# SERDES_16G0 register map
Vendor: Texas Instruments
Registers are 32-bit, read-write, reset 0x0 unless marked. A register's access mark holds for its fields unless they carry their own. Offsets are as the file gives them; [hi:lo] are bit positions.

## SERDES_16G0 (part 2 of 5)
0x00 MACRO_ID_REG ro reset 0x7364
  [15:0] MACRO_ID_TYPE — ASCII representation of sd for SerDes type.
0x04 MACRO_ID_NUMBER_REG ro reset 0x3010000
  [31:16] MACRO_ID_NUMBER — Product family in binary coded decimal.
0x08 MACRO_ID_REV_REG ro reset 0x600 — Note this read-only field may vary from product to product.
  [15:0] MACRO_ID_REV — Revision number in binary coded decimal.
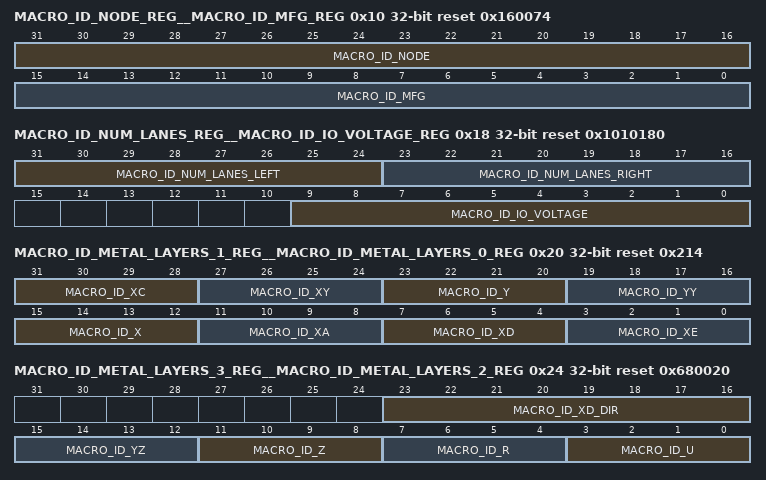
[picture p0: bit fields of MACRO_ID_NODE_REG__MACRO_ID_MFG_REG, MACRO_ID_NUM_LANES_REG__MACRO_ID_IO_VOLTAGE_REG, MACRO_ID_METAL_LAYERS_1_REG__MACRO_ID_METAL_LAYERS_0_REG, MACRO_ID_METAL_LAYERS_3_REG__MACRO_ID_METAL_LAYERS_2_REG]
0x10 MACRO_ID_NODE_REG__MACRO_ID_MFG_REG ro reset 0x160074 — Note this read-only field may vary from product to product.
  [31:16] MACRO_ID_NODE — Technology node in binary coded decimal
  [15:0] MACRO_ID_MFG — ASCII representation of the manufacturer.
0x14 MACRO_ID_FLAVOR_REG ro reset 0x6663 — Note this read-only field may vary from product to product.
  [15:0] MACRO_ID_FLAVOR — ASCII representation of fc for finfet compact flavor.
0x18 MACRO_ID_NUM_LANES_REG__MACRO_ID_IO_VOLTAGE_REG ro reset 0x1010180 — Note this read-only field may vary from product to product.
  [31:24] MACRO_ID_NUM_LANES_LEFT — The number of lanes on the left side of the common module in binary coded decimal.
  [23:16] MACRO_ID_NUM_LANES_RIGHT — The number of lanes on the right side of the common module in binary coded decimal.
  [9:0] MACRO_ID_IO_VOLTAGE — Product I/O voltage ID in binary coded decimal.
0x20 MACRO_ID_METAL_LAYERS_1_REG__MACRO_ID_METAL_LAYERS_0_REG ro reset 0x214 — Note this read-only field may vary from product to product.
  [31:28] MACRO_ID_XC — Number xc metals in stack up in binary decimal format.
  [27:24] MACRO_ID_XY — Number xy metals in stack up in binary decimal format.
  [23:20] MACRO_ID_Y — Number y metals in stack up in binary decimal format.
  [19:16] MACRO_ID_YY — Number yy metals in stack up in binary decimal format.
  [15:12] MACRO_ID_X — Number x metals in stack up in binary decimal format.
  [11:8] MACRO_ID_XA — Number xa metals in stack up in binary decimal format.
  [7:4] MACRO_ID_XD — Number xd metals in stack up in binary decimal format.
  [3:0] MACRO_ID_XE — Number xe metals in stack up in binary decimal format.
0x24 MACRO_ID_METAL_LAYERS_3_REG__MACRO_ID_METAL_LAYERS_2_REG ro reset 0x680020 — Note this read-only field may vary from product to product.
  [23:16] MACRO_ID_XD_DIR — Direction of xd metal in ASCII format.
  [15:12] MACRO_ID_YZ — Number yz metals in stack up in binary decimal format.
  [11:8] MACRO_ID_Z — Number z metals in stack up in binary decimal format.
  [7:4] MACRO_ID_R — Number r metals in stack up in binary decimal format.
  [3:0] MACRO_ID_U — Number u metals in stack up in binary decimal format.
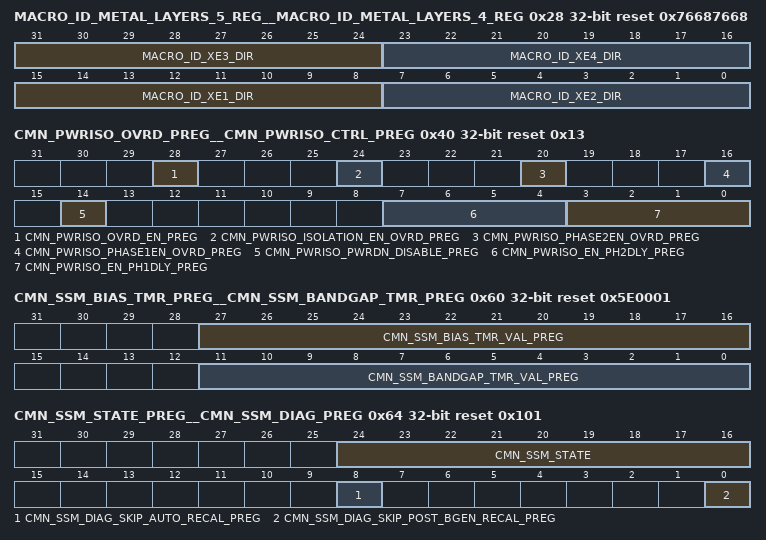
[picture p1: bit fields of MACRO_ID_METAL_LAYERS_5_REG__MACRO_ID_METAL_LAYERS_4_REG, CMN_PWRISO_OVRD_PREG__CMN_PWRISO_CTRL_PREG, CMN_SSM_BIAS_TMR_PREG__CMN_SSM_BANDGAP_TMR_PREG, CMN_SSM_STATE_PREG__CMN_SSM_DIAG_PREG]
0x28 MACRO_ID_METAL_LAYERS_5_REG__MACRO_ID_METAL_LAYERS_4_REG ro reset 0x76687668 — Note this read-only field may vary from product to product.
  [31:24] MACRO_ID_XE3_DIR — Direction of second highest lowest xe metal in ASCII format.
  [23:16] MACRO_ID_XE4_DIR — Direction of highest xe metal in ASCII format.
  [15:8] MACRO_ID_XE1_DIR — Direction of lowest xe metal in ASCII format.
  [7:0] MACRO_ID_XE2_DIR — Direction of second lowest xe metal in ASCII format.
0x40 CMN_PWRISO_OVRD_PREG__CMN_PWRISO_CTRL_PREG reset 0x13 — Common power-gated supply island control register.
  [28] CMN_PWRISO_OVRD_EN_PREG — cmn power gate active high override enable:
  [24] CMN_PWRISO_ISOLATION_EN_OVRD_PREG — cmn power gate isolation override:
  [20] CMN_PWRISO_PHASE2EN_OVRD_PREG — cmn power gate phase2en override:
  [16] CMN_PWRISO_PHASE1EN_OVRD_PREG — cmn_pwriso power gate phase1en override:
  [14] CMN_PWRISO_PWRDN_DISABLE_PREG — Power down disable:
  [7:4] CMN_PWRISO_EN_PH2DLY_PREG — Power enable phase 2 timer value:
  [3:0] CMN_PWRISO_EN_PH1DLY_PREG — Power enable phase 1 timer value:
0x60 CMN_SSM_BIAS_TMR_PREG__CMN_SSM_BANDGAP_TMR_PREG reset 0x5E0001 — Startup State Machine bandgap enable timer register.
  [27:16] CMN_SSM_BIAS_TMR_VAL_PREG — Bias enable state timer value :
  [11:0] CMN_SSM_BANDGAP_TMR_VAL_PREG — Bandgap enable state timer value :
0x64 CMN_SSM_STATE_PREG__CMN_SSM_DIAG_PREG access per field reset 0x101 — Startup State Machine diagnostic register.
  [24:16] CMN_SSM_STATE ro — Startup state machine current state:
  [8] CMN_SSM_DIAG_SKIP_AUTO_RECAL_PREG rw — Skip auto re-calibration enable : When this bit is active (1'b1), the auto calibration state will be skipped if it was previously run, unless the macro is disabled or reset.
  [0] CMN_SSM_DIAG_SKIP_POST_BGEN_RECAL_PREG rw — Skip post bandgap enable re-calibration : When this bit is active (1'b1), the post bandgap enable calibration state will be skipped if it was previously run, unless the macro is disabled or reset.
0x68 CMN_SMCSM_STATE_PREG ro — Startup State Machine Multi-cal State Machine current state register.
  [1:0] CMN_SMCSM_STATE — Startup State Machine Multi-cal State Machine current state register:
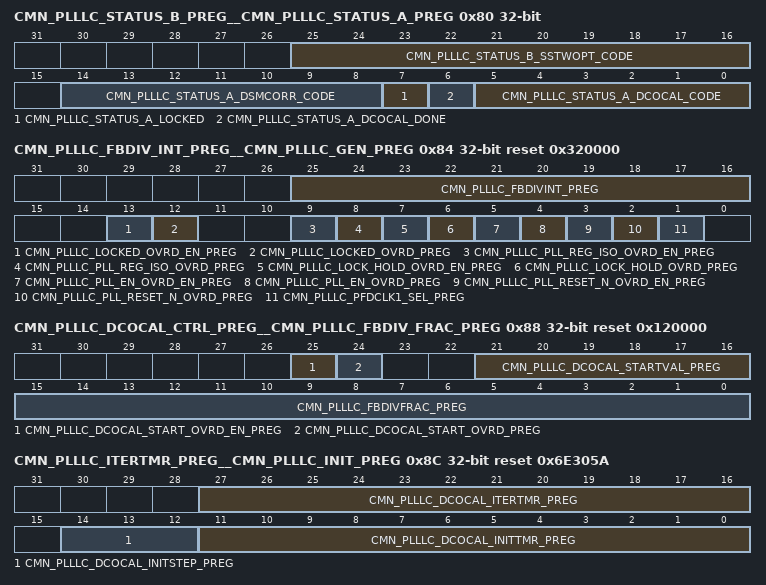
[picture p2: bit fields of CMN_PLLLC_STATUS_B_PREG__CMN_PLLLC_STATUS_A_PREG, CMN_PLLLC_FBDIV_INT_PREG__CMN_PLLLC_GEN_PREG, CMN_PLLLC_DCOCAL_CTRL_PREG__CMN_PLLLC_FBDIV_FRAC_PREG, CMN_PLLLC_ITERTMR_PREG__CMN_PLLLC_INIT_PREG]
0x80 CMN_PLLLC_STATUS_B_PREG__CMN_PLLLC_STATUS_A_PREG ro — PLLCMNLC status register A.
  [25:16] CMN_PLLLC_STATUS_B_SSTWOPT_CODE — Main PLLLC Spread Spectrum two point value result:
  [14:8] CMN_PLLLC_STATUS_A_DSMCORR_CODE — PLLCMNLC DSM spur correction code result:
  [7] CMN_PLLLC_STATUS_A_LOCKED — PLLCMNLC locked Status:
  [6] CMN_PLLLC_STATUS_A_DCOCAL_DONE — PLLCMNLC DCO calibration status:
  [5:0] CMN_PLLLC_STATUS_A_DCOCAL_CODE — PLLCMNLC DCO calibration code result:
0x84 CMN_PLLLC_FBDIV_INT_PREG__CMN_PLLLC_GEN_PREG reset 0x320000 — PLLCMNLC general control register.
  [25:16] CMN_PLLLC_FBDIVINT_PREG — This value sets the mode dependent PLLCMNLC fbdivint value.
  [13] CMN_PLLLC_LOCKED_OVRD_EN_PREG — PLLCMNLC locked active high override enable:
  [12] CMN_PLLLC_LOCKED_OVRD_PREG — PLLCMNLC locked signal force:
  [9] CMN_PLLLC_PLL_REG_ISO_OVRD_EN_PREG — PLLCMNLC regulator isolation active high override enable
  [8] CMN_PLLLC_PLL_REG_ISO_OVRD_PREG — When cmn_plllc_pll_reg_iso_ovrd_en_preg is asserted high, overrides the state dependent PLLCMNLC regulator isolation value.
  [7] CMN_PLLLC_LOCK_HOLD_OVRD_EN_PREG — Lock detection hold function active high override enable.
  [6] CMN_PLLLC_LOCK_HOLD_OVRD_PREG — When cmn_plllc_lock_hold_ovrd_en_preg is asserted high, overrides the state dependent lock detect function value.
  [5] CMN_PLLLC_PLL_EN_OVRD_EN_PREG — PLLCMNLC enable active high override enable
  [4] CMN_PLLLC_PLL_EN_OVRD_PREG — When cmn_plllc_pll_en_ovrd_en_preg is asserted high, overrides the state dependent PLLCMNLC enable value.
  [3] CMN_PLLLC_PLL_RESET_N_OVRD_EN_PREG — PLLCMNLC active high reset override enable.
  [2] CMN_PLLLC_PLL_RESET_N_OVRD_PREG — When cmn_plllc_pll_reset_n_ovrd_en_preg is asserted high, overrides the state dependent PLLCMNLC active low reset value.
  [1] CMN_PLLLC_PFDCLK1_SEL_PREG — When asserted the pfdclk1 is used as the reference clock, When deasserted, pfdclk is used.
0x88 CMN_PLLLC_DCOCAL_CTRL_PREG__CMN_PLLLC_FBDIV_FRAC_PREG reset 0x120000 — PLLCMNLC fractional feedback divider register.
  [25] CMN_PLLLC_DCOCAL_START_OVRD_EN_PREG — DCO calibration start active high override enable.
  [24] CMN_PLLLC_DCOCAL_START_OVRD_PREG — When cmn_plllc_dcocal_start_ovrd_en_preg is asserted high, this value overrides the mode dependent DCO calibration start value.
  [21:16] CMN_PLLLC_DCOCAL_STARTVAL_PREG — This value sets the DCO calibration startval value.
  [15:0] CMN_PLLLC_FBDIVFRAC_PREG — This value sets the mode dependent PLLCMNLC fbdivfrac value.
0x8C CMN_PLLLC_ITERTMR_PREG__CMN_PLLLC_INIT_PREG reset 0x6E305A — PLLCMNLC DCO calibration initialization register.
  [27:16] CMN_PLLLC_DCOCAL_ITERTMR_PREG — This value sets the DCO calibration iteration timer value.
  [14:12] CMN_PLLLC_DCOCAL_INITSTEP_PREG — This value sets the DCO calibration initialization step value.
  [11:0] CMN_PLLLC_DCOCAL_INITTMR_PREG — This value sets the DCO calibration initialization timer value.
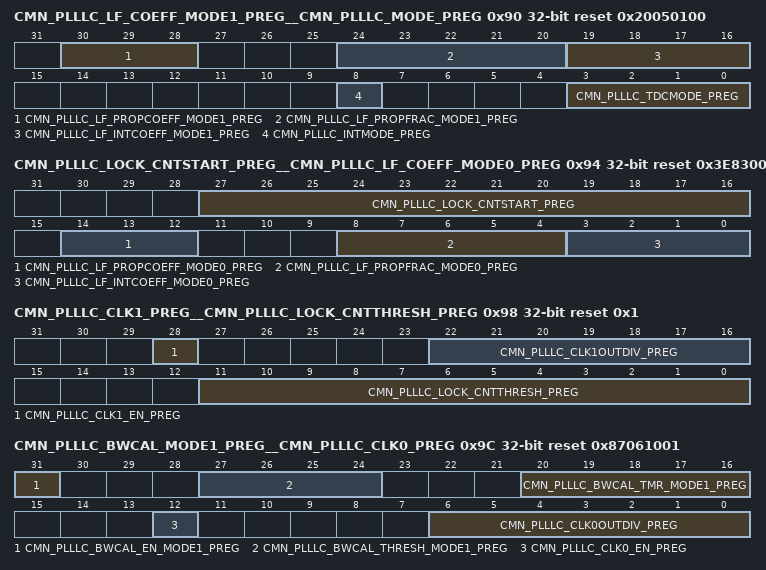
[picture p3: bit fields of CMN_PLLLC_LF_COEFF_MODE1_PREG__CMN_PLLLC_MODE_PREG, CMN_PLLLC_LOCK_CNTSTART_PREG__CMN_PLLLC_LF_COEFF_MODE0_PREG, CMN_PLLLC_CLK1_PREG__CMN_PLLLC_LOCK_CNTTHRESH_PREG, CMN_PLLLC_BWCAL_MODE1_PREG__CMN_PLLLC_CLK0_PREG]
0x90 CMN_PLLLC_LF_COEFF_MODE1_PREG__CMN_PLLLC_MODE_PREG reset 0x20050100 — PLLCMNLC mode register.
  [30:28] CMN_PLLLC_LF_PROPCOEFF_MODE1_PREG — This value sets the loop filter proportional coefficient value when cmn_plllc_mode is asserted.
  [24:20] CMN_PLLLC_LF_PROPFRAC_MODE1_PREG — This value sets the loop filter fractional coefficient value when cmn_plllc_mode is asserted.
  [19:16] CMN_PLLLC_LF_INTCOEFF_MODE1_PREG — This value sets the loop filter integer coefficient value when cmn_plllc_mode is asserted.
  [8] CMN_PLLLC_INTMODE_PREG — This value sets the integer mode value.
  [3:0] CMN_PLLLC_TDCMODE_PREG — This value sets the TDC mode value.
0x94 CMN_PLLLC_LOCK_CNTSTART_PREG__CMN_PLLLC_LF_COEFF_MODE0_PREG reset 0x3E83006 — PLLCMNLC loop filter register for mode 0.
  [27:16] CMN_PLLLC_LOCK_CNTSTART_PREG — This value sets the lock counter start value.
  [14:12] CMN_PLLLC_LF_PROPCOEFF_MODE0_PREG — This value sets the loop filter proportional coefficient value when cmn_plllc_mode is deasserted.
  [8:4] CMN_PLLLC_LF_PROPFRAC_MODE0_PREG — This value sets the loop filter fractional coefficient value when cmn_plllc_mode is deasserted.
  [3:0] CMN_PLLLC_LF_INTCOEFF_MODE0_PREG — This value sets the loop filter integer coefficient value when cmn_plllc_mode is deasserted.
0x98 CMN_PLLLC_CLK1_PREG__CMN_PLLLC_LOCK_CNTTHRESH_PREG reset 0x1 — PLLCMNLC lock count threshold register.
  [28] CMN_PLLLC_CLK1_EN_PREG — This value sets the clock1 enable value.
  [22:16] CMN_PLLLC_CLK1OUTDIV_PREG — This value sets the clock1 output divider value.
  [11:0] CMN_PLLLC_LOCK_CNTTHRESH_PREG — PLLCMNLC lock counter threshold value :
0x9C CMN_PLLLC_BWCAL_MODE1_PREG__CMN_PLLLC_CLK0_PREG reset 0x87061001 — PLLCMNLC clock0 register.
  [31] CMN_PLLLC_BWCAL_EN_MODE1_PREG — This value sets the bwcal enable value when cmn_plllc_mode is asserted.
  [27:24] CMN_PLLLC_BWCAL_THRESH_MODE1_PREG — This value sets the bwcal threshold value when cmn_plllc_mode is asserted.
  [20:16] CMN_PLLLC_BWCAL_TMR_MODE1_PREG — This value sets the bwcal timer value when cmn_plllc_mode is asserted.
  [12] CMN_PLLLC_CLK0_EN_PREG — This value sets the clock0 enable value.
  [6:0] CMN_PLLLC_CLK0OUTDIV_PREG — This value sets the clock0 output divider value.
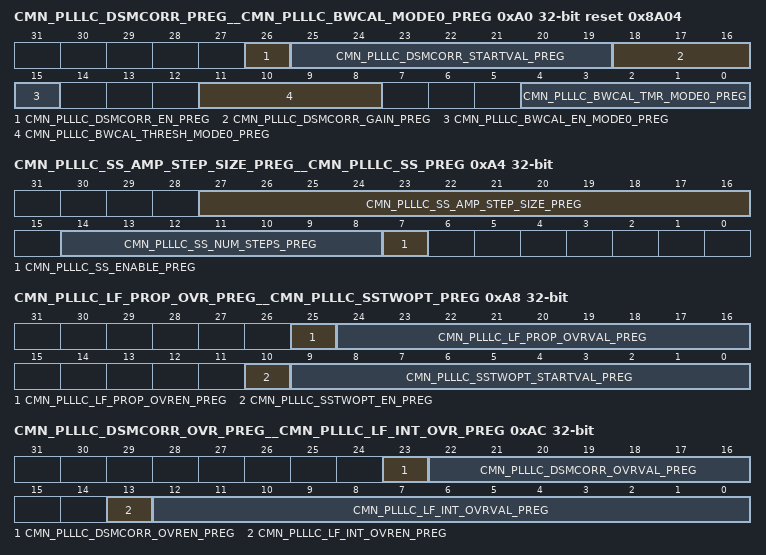
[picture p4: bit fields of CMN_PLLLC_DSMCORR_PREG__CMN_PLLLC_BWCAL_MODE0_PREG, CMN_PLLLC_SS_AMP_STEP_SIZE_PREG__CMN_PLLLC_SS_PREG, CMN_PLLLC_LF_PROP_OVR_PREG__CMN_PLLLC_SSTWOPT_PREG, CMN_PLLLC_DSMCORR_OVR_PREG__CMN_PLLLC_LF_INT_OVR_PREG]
0xA0 CMN_PLLLC_DSMCORR_PREG__CMN_PLLLC_BWCAL_MODE0_PREG reset 0x8A04 — PLLCMNLC bandwidth cal register for mode 0.
  [26] CMN_PLLLC_DSMCORR_EN_PREG — This value sets the DSM spur correction coefficient enable value.
  [25:19] CMN_PLLLC_DSMCORR_STARTVAL_PREG — This value sets the DSM spur correction coefficient startval value.
  [18:16] CMN_PLLLC_DSMCORR_GAIN_PREG — This value sets the DSM spur correction coefficient gain value.
  [15] CMN_PLLLC_BWCAL_EN_MODE0_PREG — This value sets the bwcal enable value when cmn_plllc_mode is deasserted.
  [11:8] CMN_PLLLC_BWCAL_THRESH_MODE0_PREG — This value sets the bwcal threhsold value when cmn_plllc_mode is deasserted.
  [4:0] CMN_PLLLC_BWCAL_TMR_MODE0_PREG — This value sets the bwcal timer value when cmn_plllc_mode is deasserted.
0xA4 CMN_PLLLC_SS_AMP_STEP_SIZE_PREG__CMN_PLLLC_SS_PREG — PLLCMNLC spread spectrum register.
  [27:16] CMN_PLLLC_SS_AMP_STEP_SIZE_PREG — This value sets the spread spectrum amp step size value.
  [14:8] CMN_PLLLC_SS_NUM_STEPS_PREG — This value sets the spread spectrum number of steps value.
  [7] CMN_PLLLC_SS_ENABLE_PREG — This value sets the spread spectrum enable value.
0xA8 CMN_PLLLC_LF_PROP_OVR_PREG__CMN_PLLLC_SSTWOPT_PREG — PLLCMNLC spread spectrum two point register.
  [25] CMN_PLLLC_LF_PROP_OVREN_PREG — Drives the lfprop_ovren pin on the PLLCMNLC.
  [24:16] CMN_PLLLC_LF_PROP_OVRVAL_PREG — Drives the lfprop_ovrval on the PLLCMNLC.
  [10] CMN_PLLLC_SSTWOPT_EN_PREG — This value sets the sstwopt_en pin on the PLL.
  [9:0] CMN_PLLLC_SSTWOPT_STARTVAL_PREG — This value sets the sstwoopt_startval pins on the PLL.
0xAC CMN_PLLLC_DSMCORR_OVR_PREG__CMN_PLLLC_LF_INT_OVR_PREG — PLLCMNLC debug and test loop filter integer override register.
  [23] CMN_PLLLC_DSMCORR_OVREN_PREG — Drives the dsmcorr_ovren port on the PLLCMNLC.
  [22:16] CMN_PLLLC_DSMCORR_OVRVAL_PREG — Drives the dsmcorr_ovrval port on the PLLCMNLC.
  [13] CMN_PLLLC_LF_INT_OVREN_PREG — Drives the lf_int_ovren pin on the PLLCMNLC.
  [12:0] CMN_PLLLC_LF_INT_OVRVAL_PREG — Drives the lf_int_ovrval pin on the PLLCMNLC.
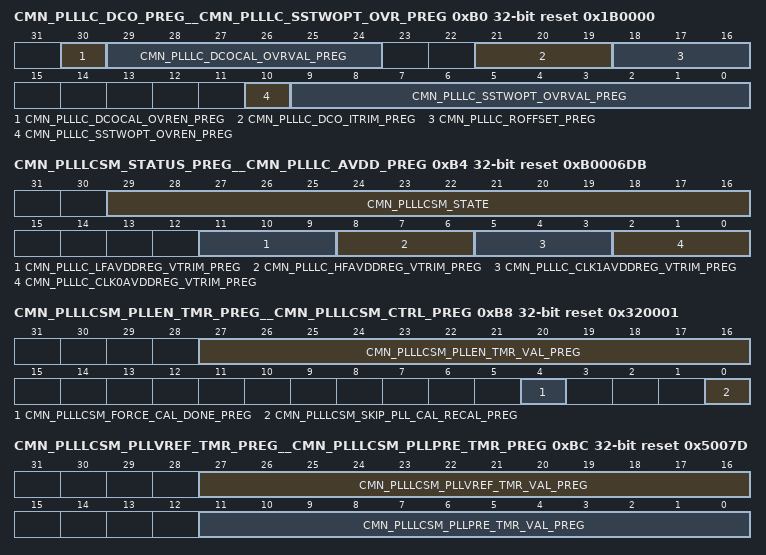
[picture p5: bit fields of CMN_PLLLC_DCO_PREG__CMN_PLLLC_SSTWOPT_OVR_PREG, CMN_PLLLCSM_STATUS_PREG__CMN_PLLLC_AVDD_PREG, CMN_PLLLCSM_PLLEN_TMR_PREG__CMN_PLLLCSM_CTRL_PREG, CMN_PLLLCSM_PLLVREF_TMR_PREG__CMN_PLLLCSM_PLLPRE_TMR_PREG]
0xB0 CMN_PLLLC_DCO_PREG__CMN_PLLLC_SSTWOPT_OVR_PREG reset 0x1B0000 — PLLCMNLC debug and test loop Spread Spectrum two point override register.
  [30] CMN_PLLLC_DCOCAL_OVREN_PREG — When asserted the cmnda_plllc_dcocal_ovren which drives the dcocal_ovren port on the PLLCMNLC is forced high.
  [29:24] CMN_PLLLC_DCOCAL_OVRVAL_PREG — When cmnda_plllc_dcocal_ovren is asserted, this value is driven onto cmnda_plllc_dcocal_ovrval which drives the dcocal_ovrval port on the PLLCMNLC.
  [21:19] CMN_PLLLC_DCO_ITRIM_PREG — Drives the DCO trim current on the PLLCMNLC.
  [18:16] CMN_PLLLC_ROFFSET_PREG — DCO tank offset resistor trim.
  [10] CMN_PLLLC_SSTWOPT_OVREN_PREG — Drives the sstwopt_ovren port on the PLLCMNLC.
  [9:0] CMN_PLLLC_SSTWOPT_OVRVAL_PREG — Drives the sstwopt_ovrval port on the PLLCMNLC.
0xB4 CMN_PLLLCSM_STATUS_PREG__CMN_PLLLC_AVDD_PREG access per field reset 0xB0006DB — PLLCMNLC debug and test avdd register.
  [29:16] CMN_PLLLCSM_STATE ro — State machine state register.
  [11:9] CMN_PLLLC_LFAVDDREG_VTRIM_PREG rw — Drives the lfavddreg_vtrim port on the PLLCMNLC.
  [8:6] CMN_PLLLC_HFAVDDREG_VTRIM_PREG rw — Drives the hfavddreg_vtrim port on the PLLCMNLC.
  [5:3] CMN_PLLLC_CLK1AVDDREG_VTRIM_PREG rw — Drives the clk1avddreg_vtrim port on the PLLCMNLC.
  [2:0] CMN_PLLLC_CLK0AVDDREG_VTRIM_PREG rw — Drives the clk0avddreg_vtrim port on the PLLCMNLC.
0xB8 CMN_PLLLCSM_PLLEN_TMR_PREG__CMN_PLLLCSM_CTRL_PREG reset 0x320001 — PLLCMNLC Control State Machine Control register.
  [27:16] CMN_PLLLCSM_PLLEN_TMR_VAL_PREG — PLL enable state timer value :
  [4] CMN_PLLLCSM_FORCE_CAL_DONE_PREG — Asserting this bit immediately advances the State Machine from the PLLSM_CAL state currently in or once entered.
  [0] CMN_PLLLCSM_SKIP_PLL_CAL_RECAL_PREG — Skip PLL calibration re-calibration enable :
0xBC CMN_PLLLCSM_PLLVREF_TMR_PREG__CMN_PLLLCSM_PLLPRE_TMR_PREG reset 0x5007D — PLLCMNLC Control State Machine PLL pre-charge timer register.
  [27:16] CMN_PLLLCSM_PLLVREF_TMR_VAL_PREG — PLL pre-charge state timer value :
  [11:0] CMN_PLLLCSM_PLLPRE_TMR_VAL_PREG — PLL pre-charge state timer value :
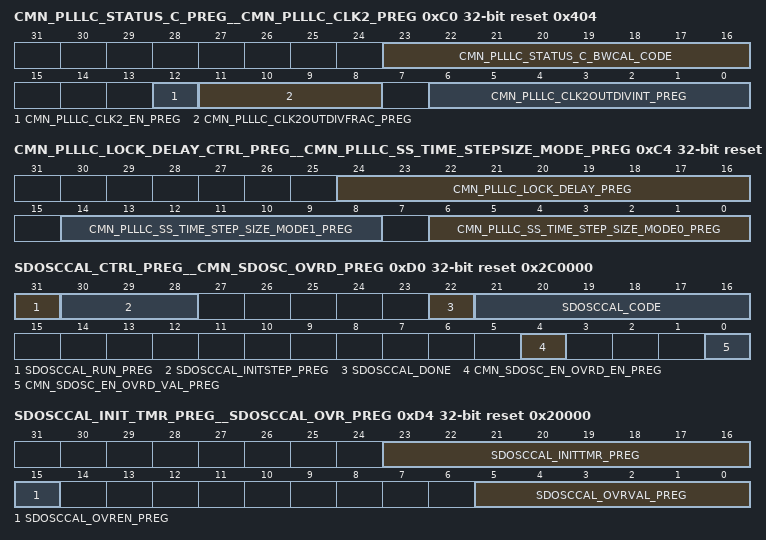
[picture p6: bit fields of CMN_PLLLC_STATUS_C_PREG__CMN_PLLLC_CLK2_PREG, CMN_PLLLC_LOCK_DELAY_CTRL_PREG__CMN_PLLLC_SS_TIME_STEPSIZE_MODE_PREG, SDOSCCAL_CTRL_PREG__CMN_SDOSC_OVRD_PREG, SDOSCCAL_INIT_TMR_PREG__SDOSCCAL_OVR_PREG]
0xC0 CMN_PLLLC_STATUS_C_PREG__CMN_PLLLC_CLK2_PREG access per field reset 0x404 — PLLCMNLC clock2 register.
  [23:16] CMN_PLLLC_STATUS_C_BWCAL_CODE ro — PLLCMNLC Band Width calibration code result:
  [12] CMN_PLLLC_CLK2_EN_PREG rw — This value sets the clock2 enable value.
  [11:8] CMN_PLLLC_CLK2OUTDIVFRAC_PREG rw — This value sets the clock2 fractional output divider's fraction value:
  [6:0] CMN_PLLLC_CLK2OUTDIVINT_PREG rw — This value sets the clock2 fractional output divider's integer value.
0xC4 CMN_PLLLC_LOCK_DELAY_CTRL_PREG__CMN_PLLLC_SS_TIME_STEPSIZE_MODE_PREG reset 0x808 — PLLCMNLC spread spectrum Time Step Size Mode register.
  [24:16] CMN_PLLLC_LOCK_DELAY_PREG — This value sets a delay from internal lock assertion to assertion of cmn_plllc_locked.
  [14:8] CMN_PLLLC_SS_TIME_STEP_SIZE_MODE1_PREG — This value sets the spread spectrum time step size value when cmn_plllc_mode is asserted.
  [6:0] CMN_PLLLC_SS_TIME_STEP_SIZE_MODE0_PREG — This value sets the spread spectrum time step size value when cmn_plllc_mode is deasserted.
0xD0 SDOSCCAL_CTRL_PREG__CMN_SDOSC_OVRD_PREG access per field reset 0x2C0000 — Signal detection oscillator override register
  [31] SDOSCCAL_RUN_PREG rw — Signal detection oscillator calibration manual initiation active high enable.
  [30:28] SDOSCCAL_INITSTEP_PREG rw — Signal detection oscillator calibration initial step size.
  [22] SDOSCCAL_DONE ro — Signal detection oscillator calibration active high complete flag.
  [21:16] SDOSCCAL_CODE ro — Signal detection oscillator calibration result.
  [4] CMN_SDOSC_EN_OVRD_EN_PREG rw — Active high override enable for the signal detection oscillator circuit enable.
  [0] CMN_SDOSC_EN_OVRD_VAL_PREG rw — When cmn_sdosc_en_ovrd_en_preg is asserted, this value drives the cmnda_sdosc_en circuit enable.
0xD4 SDOSCCAL_INIT_TMR_PREG__SDOSCCAL_OVR_PREG reset 0x20000 — Signal detection oscillator calibration override register
  [23:16] SDOSCCAL_INITTMR_PREG — Signal detection calibration initial wait timer to allow the analog circuits to settle on initiation of the calibration sequence.
  [15] SDOSCCAL_OVREN_PREG — Signal detection oscillator override active high enable.
  [5:0] SDOSCCAL_OVRVAL_PREG — When sdosccal_ovren_pregis asserted high, this value is used by the Signal detection oscillator rather than the calibration engine result.
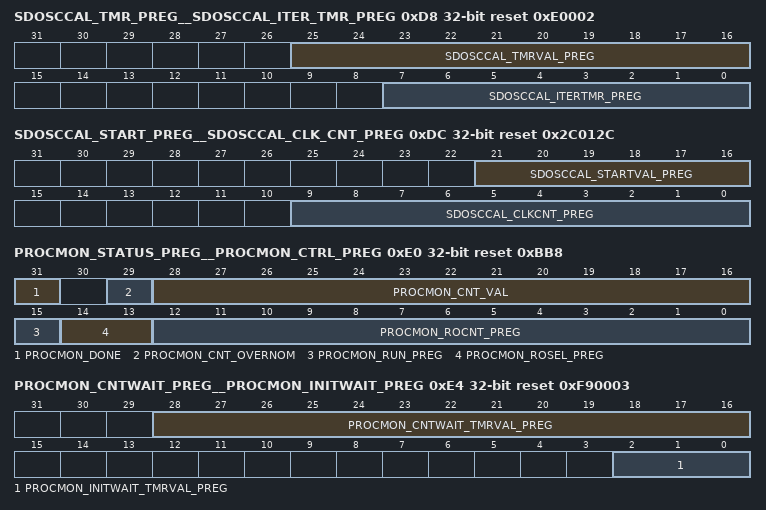
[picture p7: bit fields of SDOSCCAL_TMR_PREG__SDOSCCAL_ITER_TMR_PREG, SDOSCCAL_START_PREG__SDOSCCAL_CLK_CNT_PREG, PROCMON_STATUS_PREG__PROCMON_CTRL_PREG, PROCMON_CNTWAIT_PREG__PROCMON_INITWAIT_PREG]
0xD8 SDOSCCAL_TMR_PREG__SDOSCCAL_ITER_TMR_PREG reset 0xE0002 — Signal detection oscillator calibration iteration timer register
  [25:16] SDOSCCAL_TMRVAL_PREG — This value sets the Signal detection oscillator frequency evaluation time.
  [7:0] SDOSCCAL_ITERTMR_PREG — Signal detection calibration wait timer to allow the analog circuits to settle to the new frequency after a calibration code change.
0xDC SDOSCCAL_START_PREG__SDOSCCAL_CLK_CNT_PREG reset 0x2C012C — Signal detection oscillator calibration oscillator clock count target register
  [21:16] SDOSCCAL_STARTVAL_PREG — This value sets the Signal detection oscillator calibration starting code.
  [9:0] SDOSCCAL_CLKCNT_PREG — This value sets the Signal detection oscillator expected clock count target.
0xE0 PROCMON_STATUS_PREG__PROCMON_CTRL_PREG access per field reset 0xBB8 — Process Monitor control register.
  [31] PROCMON_DONE ro — Active high process monitor ring oscillator count complete flag.
  [29] PROCMON_CNT_OVERNOM ro — When asserted this bit indicates the process monitor ring oscillator counter reached the value expected for a nominal PVT part, as established by procmon_rocnt_preg.
  [28:16] PROCMON_CNT_VAL ro — Process monitor ring oscillator counter value.
  [15] PROCMON_RUN_PREG rw — Active high process monitor counter start.
  [14:13] PROCMON_ROSEL_PREG rw — Process monitor ring oscillator select:
  [12:0] PROCMON_ROCNT_PREG rw — Expected oscillator clocks counted for nominal process at typical conditions:
0xE4 PROCMON_CNTWAIT_PREG__PROCMON_INITWAIT_PREG reset 0xF90003 — Process Monitor initial wait timer register.
  [28:16] PROCMON_CNTWAIT_TMRVAL_PREG — Time to count the selected ring oscillator clocks.
  [2:0] PROCMON_INITWAIT_TMRVAL_PREG — Nominal number of cmn_refclk_gated clock periods to wait while the analog circuit powers up and the enabled ring oscillator settles.
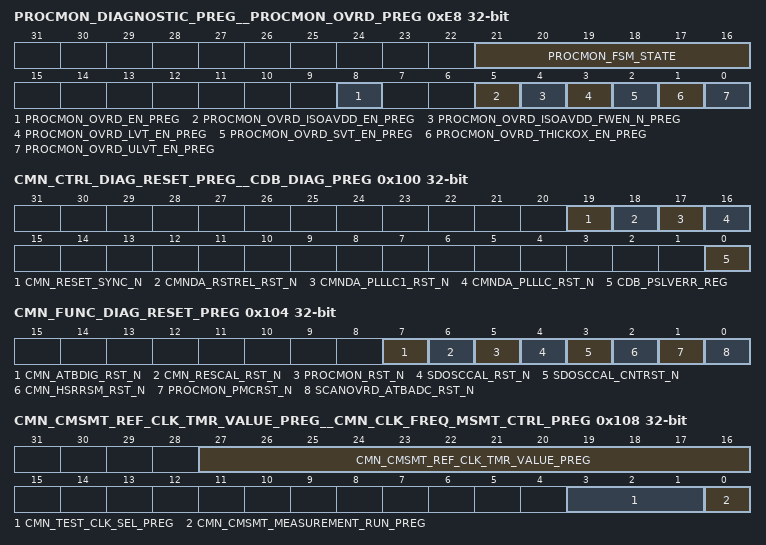
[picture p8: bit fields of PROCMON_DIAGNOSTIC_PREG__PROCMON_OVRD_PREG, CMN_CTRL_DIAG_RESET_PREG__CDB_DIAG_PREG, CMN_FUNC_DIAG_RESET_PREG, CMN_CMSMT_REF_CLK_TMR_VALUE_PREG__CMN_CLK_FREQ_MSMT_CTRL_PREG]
0xE8 PROCMON_DIAGNOSTIC_PREG__PROCMON_OVRD_PREG access per field — Process monitor override register.
  [21:16] PROCMON_FSM_STATE ro — Process monitor state machine state vector.
  [8] PROCMON_OVRD_EN_PREG rw — Active high analog control override enable.
  [5] PROCMON_OVRD_ISOAVDD_EN_PREG rw — When procmon_ovrd_en_preg is asserted, this value overrides the analog circuit's power gate enable, cmnda_pmc_isoavdd_en.
  [4] PROCMON_OVRD_ISOAVDD_FWEN_N_PREG rw — When procmon_ovrd_en_preg is asserted, this value overrides the power gate isolation control, cmnda_pmc_isoavdd_fwen_n.
  [3] PROCMON_OVRD_LVT_EN_PREG rw — When procmon_ovrd_en_preg is asserted, this value overrides the analog circuit's LVT ring oscillator enable, cmnda_pmc_lvt_en.
  [2] PROCMON_OVRD_SVT_EN_PREG rw — When procmon_ovrd_en_preg is asserted, this value overrides the analog circuit's SVT ring oscillator enable, cmnda_pmc_svt_en.
  [1] PROCMON_OVRD_THICKOX_EN_PREG rw — When procmon_ovrd_en_preg is asserted, this value overrides the analog circuit's thick oxide ring oscillator enable, cmnda_pmc_thickox_en.
  [0] PROCMON_OVRD_ULVT_EN_PREG rw — When procmon_ovrd_en_preg is asserted, this value overrides the analog circuit's ULVT ring oscillator enable, cmnda_pmc_ulvt_en.
0x100 CMN_CTRL_DIAG_RESET_PREG__CDB_DIAG_PREG ro — CDB diagnostic register.
  [19] CMN_RESET_SYNC_N — Current state of the cmn_reset_sync_n reset.
  [18] CMNDA_RSTREL_RST_N — Current state of the cmnda_rstrel_rst_n reset.
  [17] CMNDA_PLLLC1_RST_N — Current state of the cmnda_plllc1_rst_n reset.
  [16] CMNDA_PLLLC_RST_N — Current state of the cmnda_plllc_rst_n reset.
  [0] CDB_PSLVERR_REG — CDB bus error :
0x104 CMN_FUNC_DIAG_RESET_PREG ro — Common functions submodule reset diagnostic register.
  [7] CMN_ATBDIG_RST_N — Current state of the cmn_atbdig_rst_n reset.
  [6] CMN_RESCAL_RST_N — Current state of the cmn_rescal_rst_n reset.
  [5] PROCMON_RST_N — Current state of the procmon_rst_n reset.
  [4] SDOSCCAL_RST_N — Current state of the sdosccal_rst_n reset.
  [3] SDOSCCAL_CNTRST_N — Current state of the sdosccal_cntrst_n reset.
  [2] CMN_HSRRSM_RST_N — Current state of the cmn_hsrrsm_rst_n reset.
  [1] PROCMON_PMCRST_N — Current state of the procmon_pmcrst_n reset.
  [0] SCANOVRD_ATBADC_RST_N — Current state of the scanovrd_atbadc_rst_n reset.
0x108 CMN_CMSMT_REF_CLK_TMR_VALUE_PREG__CMN_CLK_FREQ_MSMT_CTRL_PREG — Common clock frequency measurement control register.
  [27:16] CMN_CMSMT_REF_CLK_TMR_VALUE_PREG — Reference clock timer value :
  [3:1] CMN_TEST_CLK_SEL_PREG — Test clock selection:
  [0] CMN_CMSMT_MEASUREMENT_RUN_PREG — Test clock measurement active high enable:
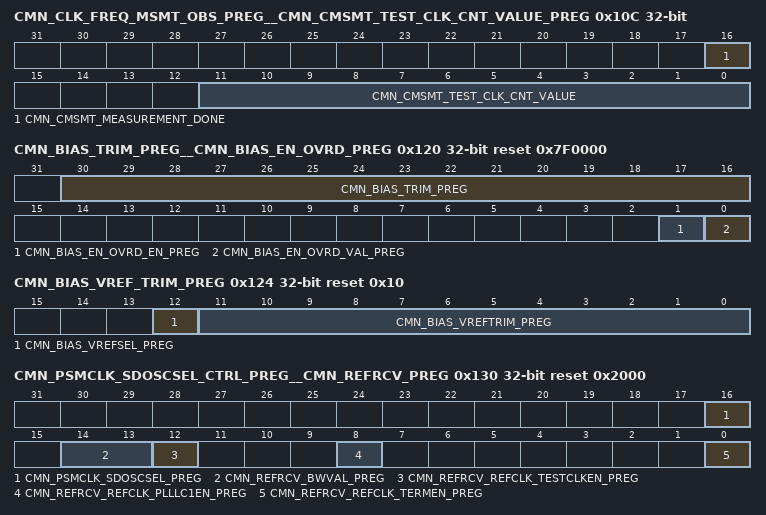
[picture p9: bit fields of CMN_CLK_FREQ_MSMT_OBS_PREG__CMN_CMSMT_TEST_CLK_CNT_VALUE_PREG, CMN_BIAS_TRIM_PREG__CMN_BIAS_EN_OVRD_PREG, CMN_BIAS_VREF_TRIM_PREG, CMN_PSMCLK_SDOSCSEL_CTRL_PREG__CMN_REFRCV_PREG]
0x10C CMN_CLK_FREQ_MSMT_OBS_PREG__CMN_CMSMT_TEST_CLK_CNT_VALUE_PREG ro — Common clock frequency measurement result register.
  [16] CMN_CMSMT_MEASUREMENT_DONE — Test clock measurement done:
  [11:0] CMN_CMSMT_TEST_CLK_CNT_VALUE — Test clock counter value:
0x110 CMN_SPARE_REG_PREG — Common spare registers to analog.
  [15:0] SPARE_PREG — Spare register bits assigned to cmnda_sparecdb.
0x120 CMN_BIAS_TRIM_PREG__CMN_BIAS_EN_OVRD_PREG reset 0x7F0000 — Bias diagnostic override register.
  [30:16] CMN_BIAS_TRIM_PREG — Drives the cmn_ana_bias block's thermometer encoded bus:
  [1] CMN_BIAS_EN_OVRD_EN_PREG — cmn_ana_bias enable active high override enable.
  [0] CMN_BIAS_EN_OVRD_VAL_PREG — When cmn_bias_en_ovrd_en_preg is asserted high, this value overrides the normal mission-mode bias enable.
0x124 CMN_BIAS_VREF_TRIM_PREG reset 0x10 — Bias debug and test voltage reference trim register.
  [12] CMN_BIAS_VREFSEL_PREG — Drives the cmn_ana_bias block vrefsel to select for voltage reference source:
  [11:0] CMN_BIAS_VREFTRIM_PREG — Drives the cmn_ana_bias block's vreftrim setting the resistor ladder voltage reference trim.
0x130 CMN_PSMCLK_SDOSCSEL_CTRL_PREG__CMN_REFRCV_PREG reset 0x2000 — Reference clock receiver register.
  [16] CMN_PSMCLK_SDOSCSEL_PREG — cmn_psmclk_out source select.
  [14:13] CMN_REFRCV_BWVAL_PREG — Bus to control the receiver bandwidth.
  [12] CMN_REFRCV_REFCLK_TESTCLKEN_PREG — Active high enable for CMOS only path from cmn_refclk_p to the digital.
  [8] CMN_REFRCV_REFCLK_PLLLC1EN_PREG — Active high enable for refclk driver to PLLCMNLC1.
  [0] CMN_REFRCV_REFCLK_TERMEN_PREG — Active high termination enable for the refclk receiver.
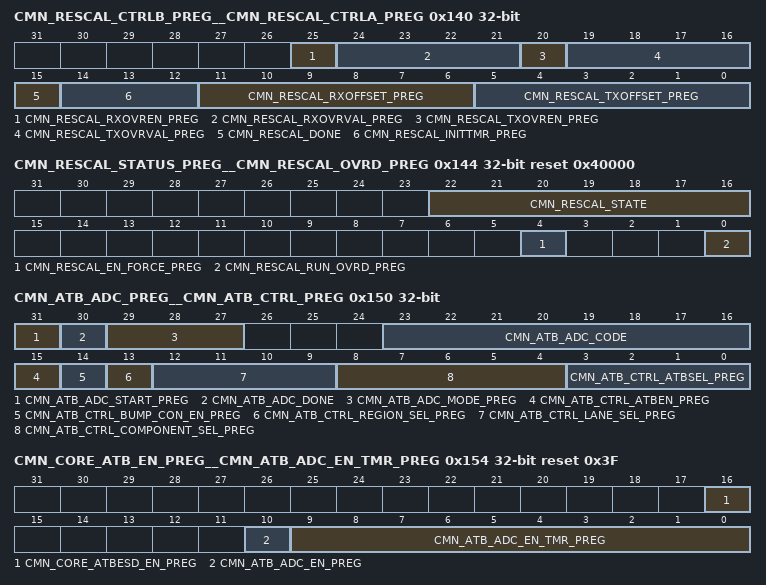
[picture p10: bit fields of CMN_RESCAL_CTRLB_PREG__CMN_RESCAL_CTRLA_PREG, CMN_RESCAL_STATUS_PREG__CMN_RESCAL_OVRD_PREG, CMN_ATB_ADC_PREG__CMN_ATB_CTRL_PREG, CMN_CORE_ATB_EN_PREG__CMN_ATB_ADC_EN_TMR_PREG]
0x140 CMN_RESCAL_CTRLB_PREG__CMN_RESCAL_CTRLA_PREG access per field — Resistor calibration debug and test control register A.
  [25] CMN_RESCAL_RXOVREN_PREG rw — RX resistor calibration LUT value active high override enable.
  [24:21] CMN_RESCAL_RXOVRVAL_PREG rw — When cmn_rescal_rxovren_preg is asserted, this value overrides the RX resistor calibration LUT value.
  [20] CMN_RESCAL_TXOVREN_PREG rw — TX resistor calibration LUT value active high override enable.
  [19:16] CMN_RESCAL_TXOVRVAL_PREG rw — When cmn_rescal_txovren_preg is asserted, this value overrides the TX resistor calibration LUT value.
  [15] CMN_RESCAL_DONE ro — Resistor calibration active high done flag.
  [14:12] CMN_RESCAL_INITTMR_PREG rw — Sets the value of the timer used to allow the clock to settle at startup and before incrementing calibration code.
  [11:6] CMN_RESCAL_RXOFFSET_PREG rw — Twos compliment offset to be added to the calibrated resistor code prior to the receive LUT.
  [5:0] CMN_RESCAL_TXOFFSET_PREG rw — Twos compliment offset to be added to the calibrated resistor code prior to the transmit LUT.
0x144 CMN_RESCAL_STATUS_PREG__CMN_RESCAL_OVRD_PREG access per field reset 0x40000 — Resistor diagnostic override register.
  [22:16] CMN_RESCAL_STATE ro — Resistor calibration FSM state vector.
  [4] CMN_RESCAL_EN_FORCE_PREG rw — Resistor calibration analog enable force.
  [0] CMN_RESCAL_RUN_OVRD_PREG rw — Resistor calibration active high run override.
0x150 CMN_ATB_ADC_PREG__CMN_ATB_CTRL_PREG access per field — ATB debug and test control register.
  [31] CMN_ATB_ADC_START_PREG rw — Active high signal that initiates the ADC to convert the ATB analog signal.
  [30] CMN_ATB_ADC_DONE ro — Active high flag indicating current conversion is complete.
  [29:27] CMN_ATB_ADC_MODE_PREG rw — Drives the mode port on the ADC selecting the input mux configuration as follows:
  [23:16] CMN_ATB_ADC_CODE ro — Current conversion results of the analog value on the ATB.
  [15] CMN_ATB_CTRL_ATBEN_PREG rw — Internal ATB active high enable.
  [14] CMN_ATB_CTRL_BUMP_CON_EN_PREG rw — ATB bump connection active high enable.
  [13] CMN_ATB_CTRL_REGION_SEL_PREG rw — ATB region select:
  [12:9] CMN_ATB_CTRL_LANE_SEL_PREG rw — ATB lane select:
  [8:4] CMN_ATB_CTRL_COMPONENT_SEL_PREG rw — ATB component select:
  [3:0] CMN_ATB_CTRL_ATBSEL_PREG rw — ATB test point select:
0x154 CMN_CORE_ATB_EN_PREG__CMN_ATB_ADC_EN_TMR_PREG reset 0x3F — ATB debug and test ADC enable and timer register.
  [16] CMN_CORE_ATBESD_EN_PREG — Core ATB pin connection active high enable.
  [10] CMN_ATB_ADC_EN_PREG — ADC enable force overriding state dependent enable:
  [9:0] CMN_ATB_ADC_EN_TMR_PREG — Enable timer value :
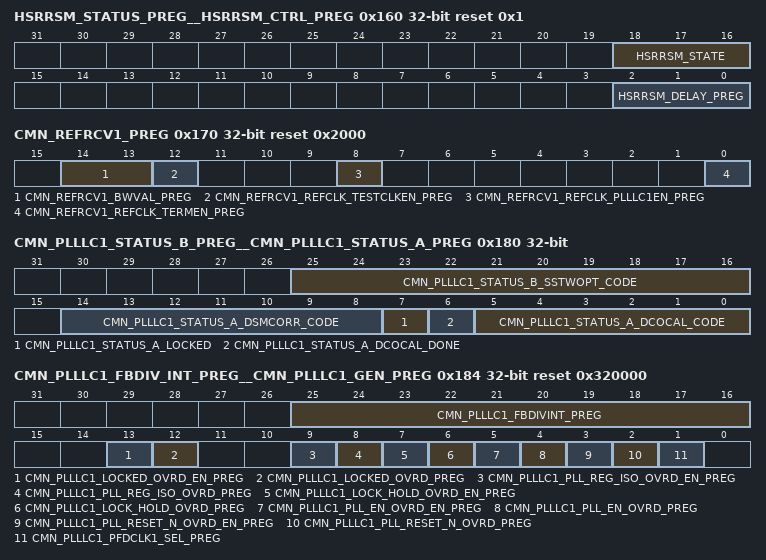
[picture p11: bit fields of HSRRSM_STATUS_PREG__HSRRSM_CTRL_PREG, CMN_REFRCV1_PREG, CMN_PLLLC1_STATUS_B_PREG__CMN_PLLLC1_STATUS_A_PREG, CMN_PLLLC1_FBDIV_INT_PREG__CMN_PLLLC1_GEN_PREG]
0x160 HSRRSM_STATUS_PREG__HSRRSM_CTRL_PREG access per field reset 0x1 — High Speed Reset Release State Machine control register.
  [18:16] HSRRSM_STATE ro — High Speed Reset Release State Machine state vector.
  [2:0] HSRRSM_DELAY_PREG rw — Reset delay :
0x170 CMN_REFRCV1_PREG reset 0x2000 — Auxiliary reference clock receiver (refrcv1) register.
  [14:13] CMN_REFRCV1_BWVAL_PREG — Bus to control the receiver bandwidth.
  [12] CMN_REFRCV1_REFCLK_TESTCLKEN_PREG — Active high enable for CMOS only path from cmn_refclk1_p to the digital.
  [8] CMN_REFRCV1_REFCLK_PLLLC1EN_PREG — Active high enable for refclk1 driver to PLLCMNLC.
  [0] CMN_REFRCV1_REFCLK_TERMEN_PREG — Active high termination enable for the refclk1 receiver.
0x180 CMN_PLLLC1_STATUS_B_PREG__CMN_PLLLC1_STATUS_A_PREG ro — PLLCMNLC1 status register A.
  [25:16] CMN_PLLLC1_STATUS_B_SSTWOPT_CODE — Main PLLLC1 Spread Spectrum two point value result:
  [14:8] CMN_PLLLC1_STATUS_A_DSMCORR_CODE — PLLCMNLC1 DSM spur correction code result:
  [7] CMN_PLLLC1_STATUS_A_LOCKED — PLLCMNLC1 locked Status:
  [6] CMN_PLLLC1_STATUS_A_DCOCAL_DONE — PLLCMNLC1 DCO calibration status:
  [5:0] CMN_PLLLC1_STATUS_A_DCOCAL_CODE — PLLCMNLC1 DCO calibration code result:
0x184 CMN_PLLLC1_FBDIV_INT_PREG__CMN_PLLLC1_GEN_PREG reset 0x320000 — PLLCMNLC1 general control register.
  [25:16] CMN_PLLLC1_FBDIVINT_PREG — This value sets the mode dependent PLLCMNLC1 fbdivint value.
  [13] CMN_PLLLC1_LOCKED_OVRD_EN_PREG — PLLCMNLC1 locked active high override enable:
  [12] CMN_PLLLC1_LOCKED_OVRD_PREG — PLLCMNLC locked signal force:
  [9] CMN_PLLLC1_PLL_REG_ISO_OVRD_EN_PREG — PLLCMNLC1 regulator isolation active high override enable
  [8] CMN_PLLLC1_PLL_REG_ISO_OVRD_PREG — When cmn_plllc1_pll_reg_iso_ovrd_en_preg is asserted high, overrides the state dependent PLLCMNLC1 regulator isolation value.
  [7] CMN_PLLLC1_LOCK_HOLD_OVRD_EN_PREG — Lock detection hold function active high override enable.
  [6] CMN_PLLLC1_LOCK_HOLD_OVRD_PREG — When cmn_plllc1_lock_hold_ovrd_en_preg is asserted high, overrides the state dependent lock detect function value.
  [5] CMN_PLLLC1_PLL_EN_OVRD_EN_PREG — PLLCMNLC1 enable active high override enable
  [4] CMN_PLLLC1_PLL_EN_OVRD_PREG — When cmn_plllc1_pll_en_ovrd_en_preg is asserted high, overrides the state dependent PLLCMNLC1 enable value.
  [3] CMN_PLLLC1_PLL_RESET_N_OVRD_EN_PREG — PLLCMNLC1 active high reset override enable.
  [2] CMN_PLLLC1_PLL_RESET_N_OVRD_PREG — When cmn_plllc1_pll_reset_n_ovrd_en_preg is asserted high, overrides the state dependent PLLCMNLC1 active low reset value.
  [1] CMN_PLLLC1_PFDCLK1_SEL_PREG — When asserted the pfdclk1 is used as the reference clock, When deasserted, pfdclk is used.
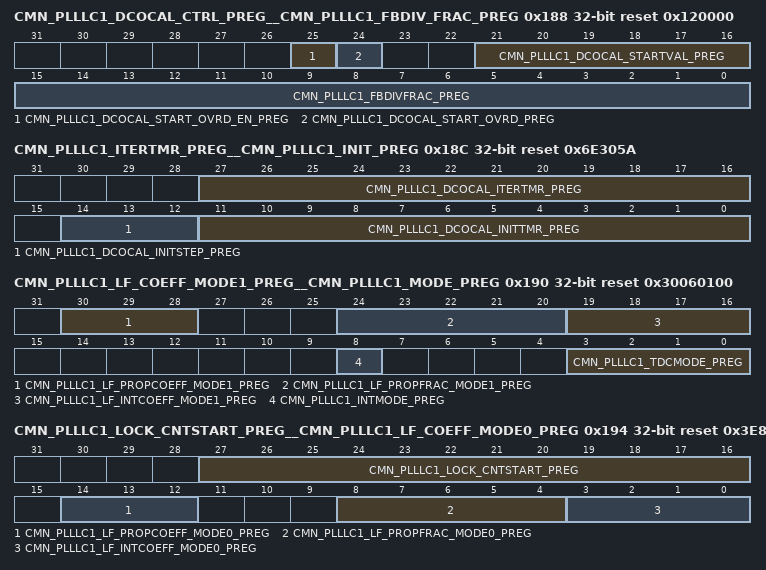
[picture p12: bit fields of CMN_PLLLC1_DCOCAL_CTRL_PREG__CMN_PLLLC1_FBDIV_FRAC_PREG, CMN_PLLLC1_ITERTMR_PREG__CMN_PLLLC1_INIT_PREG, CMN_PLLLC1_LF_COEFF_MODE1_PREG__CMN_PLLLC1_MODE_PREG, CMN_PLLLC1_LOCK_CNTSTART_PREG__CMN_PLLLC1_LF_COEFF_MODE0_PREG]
0x188 CMN_PLLLC1_DCOCAL_CTRL_PREG__CMN_PLLLC1_FBDIV_FRAC_PREG reset 0x120000 — PLLCMNLC1 fractional feedback divider register.
  [25] CMN_PLLLC1_DCOCAL_START_OVRD_EN_PREG — DCO calibration start active high override enable.
  [24] CMN_PLLLC1_DCOCAL_START_OVRD_PREG — When cmn_plllc1_dcocal_start_ovrd_en_preg is asserted high, this value overrides the mode dependent DCO calibration start value.
  [21:16] CMN_PLLLC1_DCOCAL_STARTVAL_PREG — This value sets the DCO calibration startval value.
  [15:0] CMN_PLLLC1_FBDIVFRAC_PREG — This value sets the mode dependent PLLCMNLC1 fbdivfrac value.
0x18C CMN_PLLLC1_ITERTMR_PREG__CMN_PLLLC1_INIT_PREG reset 0x6E305A — PLLCMNLC1 DCO calibration initialization register.
  [27:16] CMN_PLLLC1_DCOCAL_ITERTMR_PREG — This value sets the DCO calibration iteration timer value.
  [14:12] CMN_PLLLC1_DCOCAL_INITSTEP_PREG — This value sets the DCO calibration initialization step value.
  [11:0] CMN_PLLLC1_DCOCAL_INITTMR_PREG — This value sets the DCO calibration initialization timer value.
0x190 CMN_PLLLC1_LF_COEFF_MODE1_PREG__CMN_PLLLC1_MODE_PREG reset 0x30060100 — PLLCMNLC1 mode register.
  [30:28] CMN_PLLLC1_LF_PROPCOEFF_MODE1_PREG — This value sets the loop filter proportional coefficient value when cmn_plllc1_mode is asserted.
  [24:20] CMN_PLLLC1_LF_PROPFRAC_MODE1_PREG — This value sets the loop filter fractional coefficient value when cmn_plllc1_mode is asserted.
  [19:16] CMN_PLLLC1_LF_INTCOEFF_MODE1_PREG — This value sets the loop filter integer coefficient value when cmn_plllc1_mode is asserted.
  [8] CMN_PLLLC1_INTMODE_PREG — This value sets the integer mode value.
  [3:0] CMN_PLLLC1_TDCMODE_PREG — This value sets the TDC mode value.
0x194 CMN_PLLLC1_LOCK_CNTSTART_PREG__CMN_PLLLC1_LF_COEFF_MODE0_PREG reset 0x3E82005 — PLLCMNLC1 loop filter register for mode 0.
  [27:16] CMN_PLLLC1_LOCK_CNTSTART_PREG — This value sets the lock counter start value.
  [14:12] CMN_PLLLC1_LF_PROPCOEFF_MODE0_PREG — This value sets the loop filter proportional coefficient value when cmn_plllc1_mode is deasserted.
  [8:4] CMN_PLLLC1_LF_PROPFRAC_MODE0_PREG — This value sets the loop filter fractional coefficient value when cmn_plllc1_mode is deasserted.
  [3:0] CMN_PLLLC1_LF_INTCOEFF_MODE0_PREG — This value sets the loop filter integer coefficient value when cmn_plllc1_mode is deasserted.
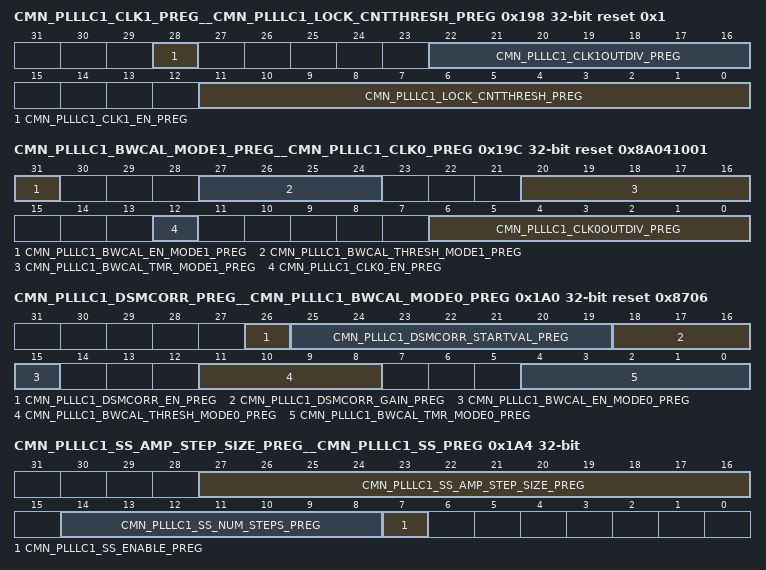
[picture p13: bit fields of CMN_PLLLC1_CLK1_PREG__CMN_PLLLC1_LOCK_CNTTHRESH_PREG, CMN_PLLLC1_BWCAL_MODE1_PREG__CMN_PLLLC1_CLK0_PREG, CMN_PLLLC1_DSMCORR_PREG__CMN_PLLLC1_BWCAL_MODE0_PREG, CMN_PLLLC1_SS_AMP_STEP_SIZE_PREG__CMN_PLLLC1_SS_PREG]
0x198 CMN_PLLLC1_CLK1_PREG__CMN_PLLLC1_LOCK_CNTTHRESH_PREG reset 0x1 — PLLCMNLC1 lock count threshold register.
  [28] CMN_PLLLC1_CLK1_EN_PREG — This value sets the clock1 enable value.
  [22:16] CMN_PLLLC1_CLK1OUTDIV_PREG — This value sets the clock1 output divider value.
  [11:0] CMN_PLLLC1_LOCK_CNTTHRESH_PREG — PLLCMNLC1 lock counter threshold value :
0x19C CMN_PLLLC1_BWCAL_MODE1_PREG__CMN_PLLLC1_CLK0_PREG reset 0x8A041001 — PLLCMNLC1 clock0 register.
  [31] CMN_PLLLC1_BWCAL_EN_MODE1_PREG — This value sets the bwcal enable value when cmn_plllc1_mode is asserted.
  [27:24] CMN_PLLLC1_BWCAL_THRESH_MODE1_PREG — This value sets the bwcal threshold value when cmn_plllc1_mode is asserted.
  [20:16] CMN_PLLLC1_BWCAL_TMR_MODE1_PREG — This value sets the bwcal timer value when cmn_plllc1_mode is asserted.
  [12] CMN_PLLLC1_CLK0_EN_PREG — This value sets the clock0 enable value.
  [6:0] CMN_PLLLC1_CLK0OUTDIV_PREG — This value sets the clock0 output divider value.
0x1A0 CMN_PLLLC1_DSMCORR_PREG__CMN_PLLLC1_BWCAL_MODE0_PREG reset 0x8706 — PLLCMNLC1 bandwidth cal register for mode 0.
  [26] CMN_PLLLC1_DSMCORR_EN_PREG — This value sets the DSM spur correction coefficient enable value.
  [25:19] CMN_PLLLC1_DSMCORR_STARTVAL_PREG — This value sets the DSM spur correction coefficient startval value.
  [18:16] CMN_PLLLC1_DSMCORR_GAIN_PREG — This value sets the DSM spur correction coefficient gain value.
  [15] CMN_PLLLC1_BWCAL_EN_MODE0_PREG — This value sets the bwcal enable value when cmn_plllc1_mode is deasserted.
  [11:8] CMN_PLLLC1_BWCAL_THRESH_MODE0_PREG — This value sets the bwcal threshold value when cmn_plllc1_mode is deasserted.
  [4:0] CMN_PLLLC1_BWCAL_TMR_MODE0_PREG — This value sets the bwcal timer value when cmn_plllc1_mode is deasserted.
0x1A4 CMN_PLLLC1_SS_AMP_STEP_SIZE_PREG__CMN_PLLLC1_SS_PREG — PLLCMNLC1 spread spectrum register.
  [27:16] CMN_PLLLC1_SS_AMP_STEP_SIZE_PREG — This value sets the spread spectrum amp step size value.
  [14:8] CMN_PLLLC1_SS_NUM_STEPS_PREG — This value sets the spread spectrum number of steps value.
  [7] CMN_PLLLC1_SS_ENABLE_PREG — This value sets the spread spectrum enable value.
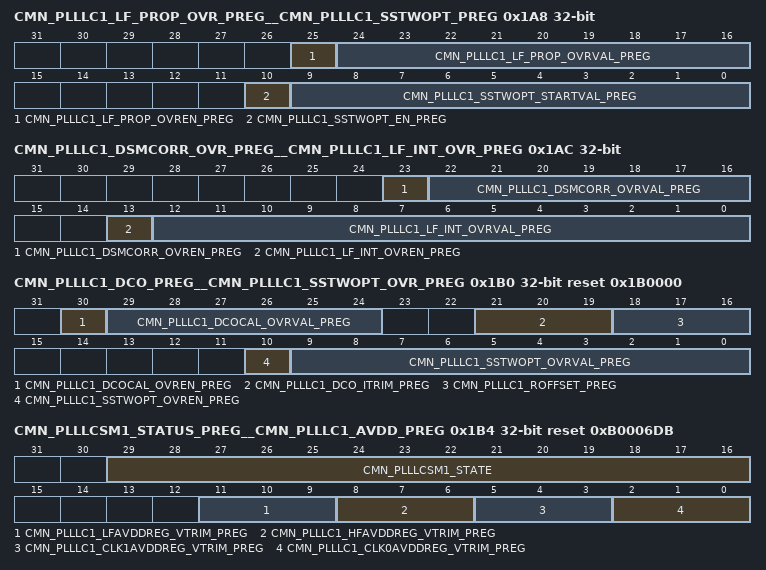
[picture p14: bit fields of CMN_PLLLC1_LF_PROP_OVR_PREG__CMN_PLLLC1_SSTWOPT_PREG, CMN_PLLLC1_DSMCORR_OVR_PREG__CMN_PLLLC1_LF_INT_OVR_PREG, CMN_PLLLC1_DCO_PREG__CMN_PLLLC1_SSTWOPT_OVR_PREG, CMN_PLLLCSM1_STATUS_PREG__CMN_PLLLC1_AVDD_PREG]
0x1A8 CMN_PLLLC1_LF_PROP_OVR_PREG__CMN_PLLLC1_SSTWOPT_PREG — PLLCMNLC1 spread spectrum two point register.
  [25] CMN_PLLLC1_LF_PROP_OVREN_PREG — Drives the lfprop_ovren pin on the PLLCMNLC1.
  [24:16] CMN_PLLLC1_LF_PROP_OVRVAL_PREG — Drives the lfprop_ovrval on the PLLCMNLC1.
  [10] CMN_PLLLC1_SSTWOPT_EN_PREG — This value sets the sstwopt_en pin on the PLL.
  [9:0] CMN_PLLLC1_SSTWOPT_STARTVAL_PREG — This value sets the sstwoopt_startval pins on the PLL.
0x1AC CMN_PLLLC1_DSMCORR_OVR_PREG__CMN_PLLLC1_LF_INT_OVR_PREG — PLLCMNLC1 debug and test loop filter integer override register.
  [23] CMN_PLLLC1_DSMCORR_OVREN_PREG — Drives the dsmcorr_ovren port on the PLLCMNLC1.
  [22:16] CMN_PLLLC1_DSMCORR_OVRVAL_PREG — Drives the dsmcorr_ovrval port on the PLLCMNLC1.
  [13] CMN_PLLLC1_LF_INT_OVREN_PREG — Drives the lf_int_ovren pin on the PLLCMNLC1.
  [12:0] CMN_PLLLC1_LF_INT_OVRVAL_PREG — Drives the lf_int_ovrval pin on the PLLCMNLC1.
0x1B0 CMN_PLLLC1_DCO_PREG__CMN_PLLLC1_SSTWOPT_OVR_PREG reset 0x1B0000 — PLLCMNLC1 debug and test loop Spread Spectrum two point override register.
  [30] CMN_PLLLC1_DCOCAL_OVREN_PREG — When asserted the cmnda_plllc1_dcocal_ovren which drives the dcocal_ovren port on the PLLCMNLC1 is forced high.
  [29:24] CMN_PLLLC1_DCOCAL_OVRVAL_PREG — When cmnda_plllc1_dcocal_ovren is asserted, this value is driven onto cmnda_plllc1_dcocal_ovrval which drives the dcocal_ovrval port on the PLLCMNLC1.
  [21:19] CMN_PLLLC1_DCO_ITRIM_PREG — Drives the DCO trim current on the PLLCMNLC1.
  [18:16] CMN_PLLLC1_ROFFSET_PREG — DCO tank offset resistor trim.
  [10] CMN_PLLLC1_SSTWOPT_OVREN_PREG — Drives the sstwopt_ovren port on the PLLCMNLC1.
  [9:0] CMN_PLLLC1_SSTWOPT_OVRVAL_PREG — Drives the sstwopt_ovrval port on the PLLCMNLC1.
0x1B4 CMN_PLLLCSM1_STATUS_PREG__CMN_PLLLC1_AVDD_PREG access per field reset 0xB0006DB — PLLCMNLC1 debug and test avdd register.
  [29:16] CMN_PLLLCSM1_STATE ro — State machine state register.
  [11:9] CMN_PLLLC1_LFAVDDREG_VTRIM_PREG rw — Drives the lfavddreg_vtrim port on the PLLCMNLC1.
  [8:6] CMN_PLLLC1_HFAVDDREG_VTRIM_PREG rw — Drives the hfavddreg_vtrim port on the PLLCMNLC1.
  [5:3] CMN_PLLLC1_CLK1AVDDREG_VTRIM_PREG rw — Drives the clk1avddreg_vtrim port on the PLLCMNLC1.
  [2:0] CMN_PLLLC1_CLK0AVDDREG_VTRIM_PREG rw — Drives the clk0avddreg_vtrim port on the PLLCMNLC1.
0x1B8 CMN_PLLLCSM1_PLLEN_TMR_PREG__CMN_PLLLCSM1_CTRL_PREG reset 0x320001 — PLLCMNLC1 Control State Machine Control register.
  [27:16] CMN_PLLLCSM1_PLLEN_TMR_VAL_PREG — PLL enable state timer value :
  [4] CMN_PLLLCSM1_FORCE_CAL_DONE_PREG — Asserting this bit immediately advances the State Machine from the PLLSM_CAL state currently in or once entered.
  [0] CMN_PLLLCSM1_SKIP_PLL_CAL_RECAL_PREG — Skip PLL calibration re-calibration enable :
0x1BC CMN_PLLLCSM1_PLLVREF_TMR_PREG__CMN_PLLLCSM1_PLLPRE_TMR_PREG reset 0x5007D — PLLCMNLC1 Control State Machine PLL pre-charge timer register.
  [27:16] CMN_PLLLCSM1_PLLVREF_TMR_VAL_PREG — PLL pre-charge state timer value :
  [11:0] CMN_PLLLCSM1_PLLPRE_TMR_VAL_PREG — PLL pre-charge state timer value :
0x1C0 CMN_PLLLC1_STATUS_C_PREG__CMN_PLLLC1_CLK2_PREG access per field reset 0x404 — PLLCMNLC1 clock2 register.
  [23:16] CMN_PLLLC1_STATUS_C_BWCAL_CODE ro — PLLCMNLC1 Band Width calibration code result:
  [12] CMN_PLLLC1_CLK2_EN_PREG rw — This value sets the clock2 enable value.
  [11:8] CMN_PLLLC1_CLK2OUTDIVFRAC_PREG rw — his value sets the clock2 fractional output divider's fraction value:
  [6:0] CMN_PLLLC1_CLK2OUTDIVINT_PREG rw — This value sets the clock2 fractional output divider's integer value.
0x1C4 CMN_PLLLC1_LOCK_DELAY_CTRL_PREG__CMN_PLLLC1_SS_TIME_STEPSIZE_MODE_PREG access per field reset 0x808 — PLLCMNLC1 spread spectrum Time Step Size Mode register.
  [31:25] CMN_PLLLC1_LOCK_DELAY_CTRL_PREG_15_9 ro — reserved
  [24:16] CMN_PLLLC1_LOCK_DELAY_PREG rw — This value sets a delay from internal lock assertion to assertion of cmn_plllc_locked.
  [14:8] CMN_PLLLC1_SS_TIME_STEP_SIZE_MODE1_PREG rw — This value sets the spread spectrum time step size value when cmn_plllc_mode is asserted.
  [6:0] CMN_PLLLC1_SS_TIME_STEP_SIZE_MODE0_PREG rw — This value sets the spread spectrum time step size value when cmn_plllc_mode is deasserted.
0x400 MOD_VER ro reset 0x69856002 — The Module and Version Register identifies the module identifier and revision of the WIZ module.
  [31:30] SCHEME — Module Scheme
  [29:28] BU — Module BU
  [27:16] MODULE_ID
  [15:11] RTL_VERSION
  [10:8] MAJOR_REVISION
  [7:6] CUSTOM_REVISION
  [5:0] MINOR_REVISION
0x404 SERDES_CTRL — Sets the SERDES control state.
  [31] POR_EN — The por_en allows the system to place the SERDES in a reset state, Access to the SERDES registers are ignored.
0x408 SERDES_TOP_CTRL reset 0xA000000 — The SERDES Top Level Control
  [31:30] PMA_CMN_REFCLK_MODE — The PMA common differential reference clock mode - Sets the mode of operation for differential reference clock input.
  [29:28] PMA_CMN_REFCLK_INT_MODE — The PMA common internal reference clock mode - Sets the mode of operation for internal reference clock input.
  [27:26] PMA_CMN_REFCLK_DIG_DIV — The PMA common reference clock digital divide ratio select - Must be set before the de-assertion of apb_preset_n/phy_reset_n.
  [25:24] PMA_CMN_REFCLK1_DIG_DIV — The Alternate reference clock digital divide select - Selects digital divide ratio for alternate reference clock coming from analog (see PMA specification for use)
  [23] PHY_PMA_SUSPEND_OVERRIDE — The PHY PMA common suspend override enable:
0x40C SERDES_RST — The SERDES Reset Register controls the Phy reset and REFCLK selection for the SERDES.
  [31] PHY_RESET_N — The PHY reset : Asserting this signal low will reset all PHY logic for the entire PHY with the exception of the APB registers and TAP controller.
  [30] PHY_EN_REFCLK — The PHY reference clock enable: When cmn_refclk_&lt;p/m&gt; is configured as a reference clock output,
  [29] PLL1_REFCLK_SEL — The PMA common PLL1 reference clock source select -
  [28] PLL0_REFCLK_SEL — The PMA common PLL0 reference clock source select -
  [27] REFCLK_TERM_DIS — The PMA common differential reference clock termination disable - enables/disables termination for difference reference clock input (cmn_refclk_&lt;p/m&gt;).
  [25:24] REFCLK_DIG_SEL — The Reference clock digital source select - Selects the reference clock source for the reference clock used in the PHY and PMA digital logic.
0x410 SERDES_TYPEC — The SERDES Type C control register allows the external lanes selection to be swapped.
  [30] LN10_SWAP — The LN10_SWAP will swap the lanes 0 and 1.
0x414 SERDES_CORE_STATUS ro — The contains SERDES core power state status.
  [31] MACRO_PWR_EN_ACK — SERDES macro_power enable acknowledgment - This signal is asserted high, upon completion of the power on sequence in the SERDES.
0x480 LANECTL0 — The Lane Control Register sets the lane specific modes of operation.
  [31] P0_ENABLE — The P0_ENABLE is AND'ed with the IPx_LNy_reset_n to enable the lane.
  [30] P0_FORCE_ENABLE — The P0_FORCE_ENABLE is OR'ed with the IPx_LNy_reset_n to force enable the lane.
  [29] P0_ALIGN — The P0_ALIGN will auto align the RAW interface to 8B10B comma characters.
  [28] P0_RAW_AUTO_START — The P0_RAW_AUTO_START will auto sequence the RAW interface according to the configuration settings
  [25:24] P0_STANDARD_MODE — Standard Mode
  [23:22] P0_FULLRT_DIV — Full Rate divider for 2x MAC speed mode.
  [21:20] P0_MAC_SRC_SEL — MAC clock source select: Selects which PMA clock to use as clock source for pcs_mac_clk*_ln_0 signals.
  [19:18] P0_REFCLK_SEL — Refclk Select determines which clocks will be used for the IP refclk signal.
  [17:16] P0_OVR_SRC_SEL — Oversample clock source select: Selects which PMA clock to use as clock source for pcs_ovr_clk*_ln_0.
  [14:12] P0_OVR_DIV_SEL — Oversample clock divider ratio select: Selects the divider ratio for pcs_ovr_clk_divx_ln_0.
  [11:10] P0_SUBCLK_SEL — Selects which clock sources pcs_sub_clk_0.
  [9:8] P0_TXFCLK_SEL — Fclk Select determines which clocks will be used for the IP txfclk signal.
  [7:6] P0_RXFCLK_SEL — Fclk Select determines which clocks will be used for the IP rxfclk signal.
0x484 LANEDIV0 — The Lane Divider Register sets the lane specific dividers of
  [22:16] P0_MAC_DIV_SEL0 — The reg_p0_mac_div_sel0 controls the divider for lane 0 MAC clock divider ratio select : Selects the divider ratio for pcs_mac_clk_divx0_ln_*.
  [8:0] P0_MAC_DIV_SEL1 — The reg_p0_mac_div_sel1 controls the divider for lane 0 MAC clock divider ratio select : Selects the divider ratio for pcs_mac_clk_divx1_ln_*.
0x488 LANALIGN0 ro — The Lane Align reports the 8B10B alignment delay from the Comma aligner when 8B10B protocol is used in RAW mode.
  [5:0] P0_ALIGN_RX_DELAY — The reg_p0_align_rx_delay indicates the number of bits that are added to align the data to an 8B10B alignment.
0x48C LANESTS0 ro — The lane Status reports the lane state information for debug purposes.
  [1] P0_MASTER — The reg_p0_master indicates the lane is a base lane for a multi lane link.
  [0] P0_PWR_EN_ACK — The reg_p0_pwr_en_ack SERDES lane power enable acknowledgment - This signal is asserted high, upon completion of the power on sequence in each PMA transceiver link (per-link/shared signal).
0x4C0 LANECTL1 — The Lane Control Register sets the lane specific modes of operation.
  [31] P1_ENABLE — The p1_enable is AND'd with the IPx_LNy_reset_n to enable the lane.
  [30] P1_FORCE_ENABLE — The p1_force_enable is OR'd with the IPx_LNy_reset_n to force enable the lane.
  [29] P1_ALIGN — The p1_align will auto align the RAW interface to 8B10B comma characters.
  [28] P1_RAW_AUTO_START — The p1_raw_auto_start will auto sequence the RAW interface according to the configuration settings
  [25:24] P1_STANDARD_MODE — Standard Mode
  [23:22] P1_FULLRT_DIV — Full Rate divider for 2x MAC speed mode.
  [21:20] P1_MAC_SRC_SEL — MAC clock source select: Selects which PMA clock to use as clock source for pcs_mac_clk*_ln_1 signals.
  [19:18] P1_REFCLK_SEL — Refclk Select determines which clocks will be used for the IP refclk signal.
  [17:16] P1_OVR_SRC_SEL — Oversample clock source select: Selects which PMA clock to use as clock source for pcs_ovr_clk*_ln_1.
  [14:12] P1_OVR_DIV_SEL — Oversample clock divider ratio select: Selects the divider ratio for pcs_ovr_clk_divx_ln_1.
  [11:10] P1_SUBCLK_SEL — Selects which clock sources pcs_sub_clk_1.
  [9:8] P1_TXFCLK_SEL — Fclk Select determines which clocks will be used for the IP txfclk signal.
  [7:6] P1_RXFCLK_SEL — Fclk Select determines which clocks will be used for the IP rxfclk signal.
0x4C4 LANEDIV1 — The Lane Divider Register sets the lane specific dividers of
  [22:16] P1_MAC_DIV_SEL0 — The reg_p1_mac_div_sel0 controls the divider for lane 1 MAC clock divider ratio select : Selects the divider ratio for pcs_mac_clk_divx0_ln_*.
  [8:0] P1_MAC_DIV_SEL1 — The reg_p1_mac_div_sel1 controls the divider for lane 1 MAC clock divider ratio select : Selects the divider ratio for pcs_mac_clk_divx1_ln_*.
0x4C8 LANALIGN1 ro — The Lane Align reports the 8B10B alignment delay from the Comma aligner when 8B10B protocol is used in RAW mode.
  [5:0] P1_ALIGN_RX_DELAY — The reg_p1_align_rx_delay indicates the number of bits that are added to align the data to an 8B10B alignment.
0x4CC LANESTS1 ro — The lane Status reports the lane state information for debug purposes.
  [1] P1_MASTER — The reg_p1_master indicates the lane is a base lane for a multi lane link.
  [0] P1_PWR_EN_ACK — The reg_p1_pwr_en_ack SERDES lane power enable acknowledgment - This signal is asserted high, upon completion of the power on sequence in each PMA transceiver link (per-link/shared signal).
